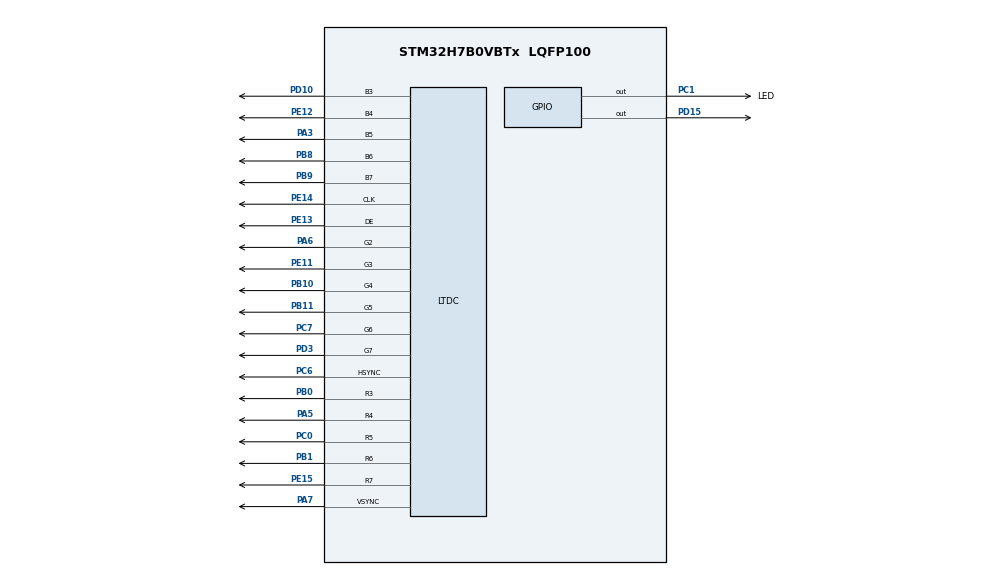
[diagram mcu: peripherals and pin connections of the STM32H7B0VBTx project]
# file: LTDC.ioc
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CORTEX_M7.AccessPermission_Spec=MPU_REGION_FULL_ACCESS
CORTEX_M7.BaseAddress_Spec=0x24000000
CORTEX_M7.CPU_DCache=Enabled
CORTEX_M7.CPU_ICache=Enabled
CORTEX_M7.DisableExec_Spec=MPU_INSTRUCTION_ACCESS_ENABLE
CORTEX_M7.IsCacheable_Spec=MPU_ACCESS_NOT_CACHEABLE
CORTEX_M7.IsShareable_Spec=MPU_ACCESS_NOT_SHAREABLE
CORTEX_M7.Size_Spec=MPU_REGION_SIZE_1MB
CORTEX_M7.SubRegionDisable_Spec=0x00
CORTEX_M7.default_mode_Activation=1
LTDC.ActiveW=800
LTDC.Alpha_L0=255
LTDC.FBStartAdress_L0=0x24000000
LTDC.HBP=46
LTDC.HFP=22
LTDC.HSync=1
LTDC.ImageHeight_L0=480
LTDC.ImageWidth_L0=800
LTDC.Layers=0
LTDC.PixelFormat_L0=LTDC_PIXEL_FORMAT_RGB565
LTDC.VBP=23
LTDC.VFP=22
LTDC.VSync=1
LTDC.WindowX1_L0=800
LTDC.WindowY1_L0=480
Mcu.Family=STM32H7
Mcu.Name=STM32H7B0VBTx
Mcu.Package=LQFP100
NVIC.PriorityGroup=NVIC_PRIORITYGROUP_4
PA1.GPIO_Speed=GPIO_SPEED_FREQ_VERY_HIGH
PA1.Signal=LTDC_R2
PA13.Mode=Serial_Wire
PA13.Signal=DEBUG_JTMS-SWDIO
PA14.Mode=Serial_Wire
PA14.Signal=DEBUG_JTCK-SWCLK
PA3.GPIO_Speed=GPIO_SPEED_FREQ_VERY_HIGH
PA3.Mode=RGB565
PA3.Signal=LTDC_B5
PA5.GPIO_Speed=GPIO_SPEED_FREQ_VERY_HIGH
PA5.Mode=RGB565
PA5.Signal=LTDC_R4
PA6.GPIO_Speed=GPIO_SPEED_FREQ_VERY_HIGH
PA6.Mode=RGB565
PA6.Signal=LTDC_G2
PA7.GPIO_Speed=GPIO_SPEED_FREQ_VERY_HIGH
PA7.Mode=RGB565
PA7.Signal=LTDC_VSYNC
PB0.GPIO_Speed=GPIO_SPEED_FREQ_VERY_HIGH
PB0.Mode=RGB565
PB0.Signal=LTDC_R3
PB1.GPIO_Speed=GPIO_SPEED_FREQ_VERY_HIGH
PB1.Mode=RGB565
PB1.Signal=LTDC_R6
PB10.GPIO_Speed=GPIO_SPEED_FREQ_VERY_HIGH
PB10.Mode=RGB565
PB10.Signal=LTDC_G4
PB11.GPIO_Speed=GPIO_SPEED_FREQ_VERY_HIGH
PB11.Mode=RGB565
PB11.Signal=LTDC_G5
PB8.GPIO_Speed=GPIO_SPEED_FREQ_VERY_HIGH
PB8.Mode=RGB565
PB8.Signal=LTDC_B6
PB9.GPIO_Speed=GPIO_SPEED_FREQ_VERY_HIGH
PB9.Mode=RGB565
PB9.Signal=LTDC_B7
PC0.GPIO_Speed=GPIO_SPEED_FREQ_VERY_HIGH
PC0.Mode=RGB565
PC0.Signal=LTDC_R5
PC1.GPIO_Label=LED
PC1.GPIO_ModeDefaultOutputPP=GPIO_MODE_OUTPUT_PP
PC1.GPIO_PuPd=GPIO_NOPULL
PC1.GPIO_Speed=GPIO_SPEED_FREQ_HIGH
PC1.PinState=GPIO_PIN_SET
PC1.Signal=GPIO_Output
PC14-OSC32_IN.Mode=LSE-External-Oscillator
PC14-OSC32_IN.Signal=RCC_OSC32_IN
PC15-OSC32_OUT.Mode=LSE-External-Oscillator
PC15-OSC32_OUT.Signal=RCC_OSC32_OUT
PC6.GPIO_Speed=GPIO_SPEED_FREQ_VERY_HIGH
PC6.Mode=RGB565
PC6.Signal=LTDC_HSYNC
PC7.GPIO_Speed=GPIO_SPEED_FREQ_VERY_HIGH
PC7.Mode=RGB565
PC7.Signal=LTDC_G6
PD10.GPIO_Speed=GPIO_SPEED_FREQ_VERY_HIGH
PD10.Mode=RGB565
PD10.Signal=LTDC_B3
PD15.GPIO_PuPd=GPIO_PULLUP
PD15.PinState=GPIO_PIN_SET
PD15.Signal=GPIO_Output
PD3.GPIO_Speed=GPIO_SPEED_FREQ_VERY_HIGH
PD3.Mode=RGB565
PD3.Signal=LTDC_G7
PD6.GPIO_Speed=GPIO_SPEED_FREQ_VERY_HIGH
PD6.Signal=LTDC_B2
PE11.GPIO_Speed=GPIO_SPEED_FREQ_VERY_HIGH
PE11.Mode=RGB565
PE11.Signal=LTDC_G3
PE12.GPIO_Speed=GPIO_SPEED_FREQ_VERY_HIGH
PE12.Mode=RGB565
PE12.Signal=LTDC_B4
PE13.GPIO_Speed=GPIO_SPEED_FREQ_VERY_HIGH
PE13.Mode=RGB565
PE13.Signal=LTDC_DE
PE14.GPIO_Speed=GPIO_SPEED_FREQ_VERY_HIGH
PE14.Mode=RGB565
PE14.Signal=LTDC_CLK
PE15.GPIO_Speed=GPIO_SPEED_FREQ_VERY_HIGH
PE15.Mode=RGB565
PE15.Signal=LTDC_R7
PH0-OSC_IN.Mode=HSE-External-Oscillator
PH0-OSC_IN.Signal=RCC_OSC_IN
PH1-OSC_OUT.Mode=HSE-External-Oscillator
PH1-OSC_OUT.Signal=RCC_OSC_OUT
ProjectManager.HeapSize=0x200
ProjectManager.StackSize=0x400
ProjectManager.TargetToolchain=STM32CubeIDE
RCC.ADCFreq_Value=280000000
RCC.APB1Freq_Value=140000000
RCC.APB2Freq_Value=140000000
RCC.APB3Freq_Value=140000000
RCC.APB4Freq_Value=140000000
RCC.CDPPRE=RCC_APB3_DIV2
RCC.CDPPRE1=RCC_APB1_DIV2
RCC.CDPPRE2=RCC_APB2_DIV2
RCC.CortexFreq_Value=280000000
RCC.DIVM1=5
RCC.DIVM2=5
RCC.DIVM3=25
RCC.DIVN1=112
RCC.DIVN2=112
RCC.DIVN3=330
RCC.DIVR3=10
RCC.FLatency=FLASH_LATENCY_7
RCC.HCLKFreq_Value=280000000
RCC.HSE_VALUE=25000000
RCC.PLLFRACN=0
RCC.PLLSourceVirtual=RCC_PLLSOURCE_HSE
RCC.SRDPPRE=RCC_APB4_DIV2
RCC.SYSCLKFreq_VALUE=280000000
RCC.SYSCLKSource=RCC_SYSCLKSOURCE_PLLCLK
RCC.USBFreq_Value=280000000
board=custom

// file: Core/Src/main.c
/* USER CODE BEGIN Header */
/**
  ******************************************************************************
  * @file           : main.c
  * @brief          : Main program body
  ******************************************************************************
  * @attention
  *
  * Copyright (c) 2023 STMicroelectronics.
  * All rights reserved.
  *
  * This software is licensed under terms that can be found in the LICENSE file
  * in the root directory of this software component.
  * If no LICENSE file comes with this software, it is provided AS-IS.
  *
  ******************************************************************************
  */
/* USER CODE END Header */
#include "main.h"
#include "ltdc.h"
#include "gpio.h"

void SystemClock_Config(void);
static void MPU_Config(void);

int main(void)
{
  /* USER CODE BEGIN 1 */
    uint32_t i; 				// 计数变量
  /* USER CODE END 1 */

  /* MPU Configuration--------------------------------------------------------*/
  MPU_Config();

  /* Enable I-Cache---------------------------------------------------------*/
  SCB_EnableICache();

  /* Enable D-Cache---------------------------------------------------------*/
  SCB_EnableDCache();

  /* MCU Configuration--------------------------------------------------------*/

  /* Reset of all peripherals, Initializes the Flash interface and the Systick. */
  HAL_Init();

  /* Configure the system clock */
  SystemClock_Config();

  /* Initialize all configured peripherals */
  MX_GPIO_Init();
  MX_LTDC_Init();
  /* USER CODE BEGIN 2 */

//  刷屏函数，可自行更改
    while( LTDC->CDSR != 0X00000001);
    for(i=0;i<(800*480);i++)
    {
        *(__IO uint16_t*)( 0x24000000 + i*2 ) = 0xFFFF; 	// 写入显存
    }

  /* USER CODE END 2 */

  /* Infinite loop */
  while (1)
  {

    /* USER CODE BEGIN 3 */
      HAL_GPIO_TogglePin(LED_GPIO_Port, LED_Pin);
      HAL_Delay(100);
  }
  /* USER CODE END 3 */
}

void SystemClock_Config(void)
{
  RCC_OscInitTypeDef RCC_OscInitStruct = {0};
  RCC_ClkInitTypeDef RCC_ClkInitStruct = {0};

  /*AXI clock gating */
  RCC->CKGAENR = 0xFFFFFFFF;

  /** Supply configuration update enable
  */
  HAL_PWREx_ConfigSupply(PWR_LDO_SUPPLY);

  /** Configure the main internal regulator output voltage
  */
  __HAL_PWR_VOLTAGESCALING_CONFIG(PWR_REGULATOR_VOLTAGE_SCALE0);

  while(!__HAL_PWR_GET_FLAG(PWR_FLAG_VOSRDY)) {}

  /** Initializes the RCC Oscillators according to the specified parameters
  * in the RCC_OscInitTypeDef structure.
  */
  RCC_OscInitStruct.OscillatorType = RCC_OSCILLATORTYPE_HSE;
  RCC_OscInitStruct.HSEState = RCC_HSE_ON;
  RCC_OscInitStruct.PLL.PLLState = RCC_PLL_ON;
  RCC_OscInitStruct.PLL.PLLSource = RCC_PLLSOURCE_HSE;
  RCC_OscInitStruct.PLL.PLLM = 5;
  RCC_OscInitStruct.PLL.PLLN = 112;
  RCC_OscInitStruct.PLL.PLLP = 2;
  RCC_OscInitStruct.PLL.PLLQ = 2;
  RCC_OscInitStruct.PLL.PLLR = 2;
  RCC_OscInitStruct.PLL.PLLRGE = RCC_PLL1VCIRANGE_2;
  RCC_OscInitStruct.PLL.PLLVCOSEL = RCC_PLL1VCOWIDE;
  RCC_OscInitStruct.PLL.PLLFRACN = 0;
  if (HAL_RCC_OscConfig(&RCC_OscInitStruct) != HAL_OK)
  {
    Error_Handler();
  }

  /** Initializes the CPU, AHB and APB buses clocks
  */
  RCC_ClkInitStruct.ClockType = RCC_CLOCKTYPE_HCLK|RCC_CLOCKTYPE_SYSCLK
                              |RCC_CLOCKTYPE_PCLK1|RCC_CLOCKTYPE_PCLK2
                              |RCC_CLOCKTYPE_D3PCLK1|RCC_CLOCKTYPE_D1PCLK1;
  RCC_ClkInitStruct.SYSCLKSource = RCC_SYSCLKSOURCE_PLLCLK;
  RCC_ClkInitStruct.SYSCLKDivider = RCC_SYSCLK_DIV1;
  RCC_ClkInitStruct.AHBCLKDivider = RCC_HCLK_DIV1;
  RCC_ClkInitStruct.APB3CLKDivider = RCC_APB3_DIV2;
  RCC_ClkInitStruct.APB1CLKDivider = RCC_APB1_DIV2;
  RCC_ClkInitStruct.APB2CLKDivider = RCC_APB2_DIV2;
  RCC_ClkInitStruct.APB4CLKDivider = RCC_APB4_DIV2;

  if (HAL_RCC_ClockConfig(&RCC_ClkInitStruct, FLASH_LATENCY_7) != HAL_OK)
  {
    Error_Handler();
  }
}

/* MPU Configuration */

void MPU_Config(void)
{
  MPU_Region_InitTypeDef MPU_InitStruct = {0};

  /* Disables the MPU */
  HAL_MPU_Disable();

  /** Initializes and configures the Region and the memory to be protected
  */
  MPU_InitStruct.Enable = MPU_REGION_ENABLE;
  MPU_InitStruct.Number = MPU_REGION_NUMBER0;
  MPU_InitStruct.BaseAddress = 0x24000000;
  MPU_InitStruct.Size = MPU_REGION_SIZE_1MB;
  MPU_InitStruct.SubRegionDisable = 0x00;
  MPU_InitStruct.TypeExtField = MPU_TEX_LEVEL0;
  MPU_InitStruct.AccessPermission = MPU_REGION_FULL_ACCESS;
  MPU_InitStruct.DisableExec = MPU_INSTRUCTION_ACCESS_ENABLE;
  MPU_InitStruct.IsShareable = MPU_ACCESS_NOT_SHAREABLE;
  MPU_InitStruct.IsCacheable = MPU_ACCESS_NOT_CACHEABLE;
  MPU_InitStruct.IsBufferable = MPU_ACCESS_NOT_BUFFERABLE;

  HAL_MPU_ConfigRegion(&MPU_InitStruct);
  /* Enables the MPU */
  HAL_MPU_Enable(MPU_PRIVILEGED_DEFAULT);

}

void Error_Handler(void)
{
  __disable_irq();
  while (1)
  {
  }
}
